# SYNTH32B register map
File version: 1.0
Synthetic device B for diff tests
Registers are 32-bit, read-write, reset 0x200 unless marked. A register's access mark holds for its fields unless they carry their own. Offsets are from the block's base; lines under a group give offsets from that group; [hi:lo] are bit positions; {n}, {i} and the like mark numbered series; 'fields as' and 'values as' point back to an identical list; <NAME> marks a mode.

## Memory map
0x40013C00 USART1 — Synthetic USART 1 (B)

## USART1 — Synthetic USART 1 (B)
Base 0x40013C00
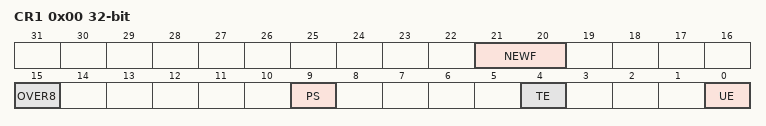
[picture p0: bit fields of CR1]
0x00 CR1 — Control register 1
  [21:20] NEWF — Only on device B
  [15] OVER8 — Oversampling mode
  [9] PS ro — Parity selection
    0=EVEN (Even parity)
  [4] TE — Transmitter enable
  [0] UE — USART enable
